AUTOSAR XML (schema 00046)
package /ComponentTypes
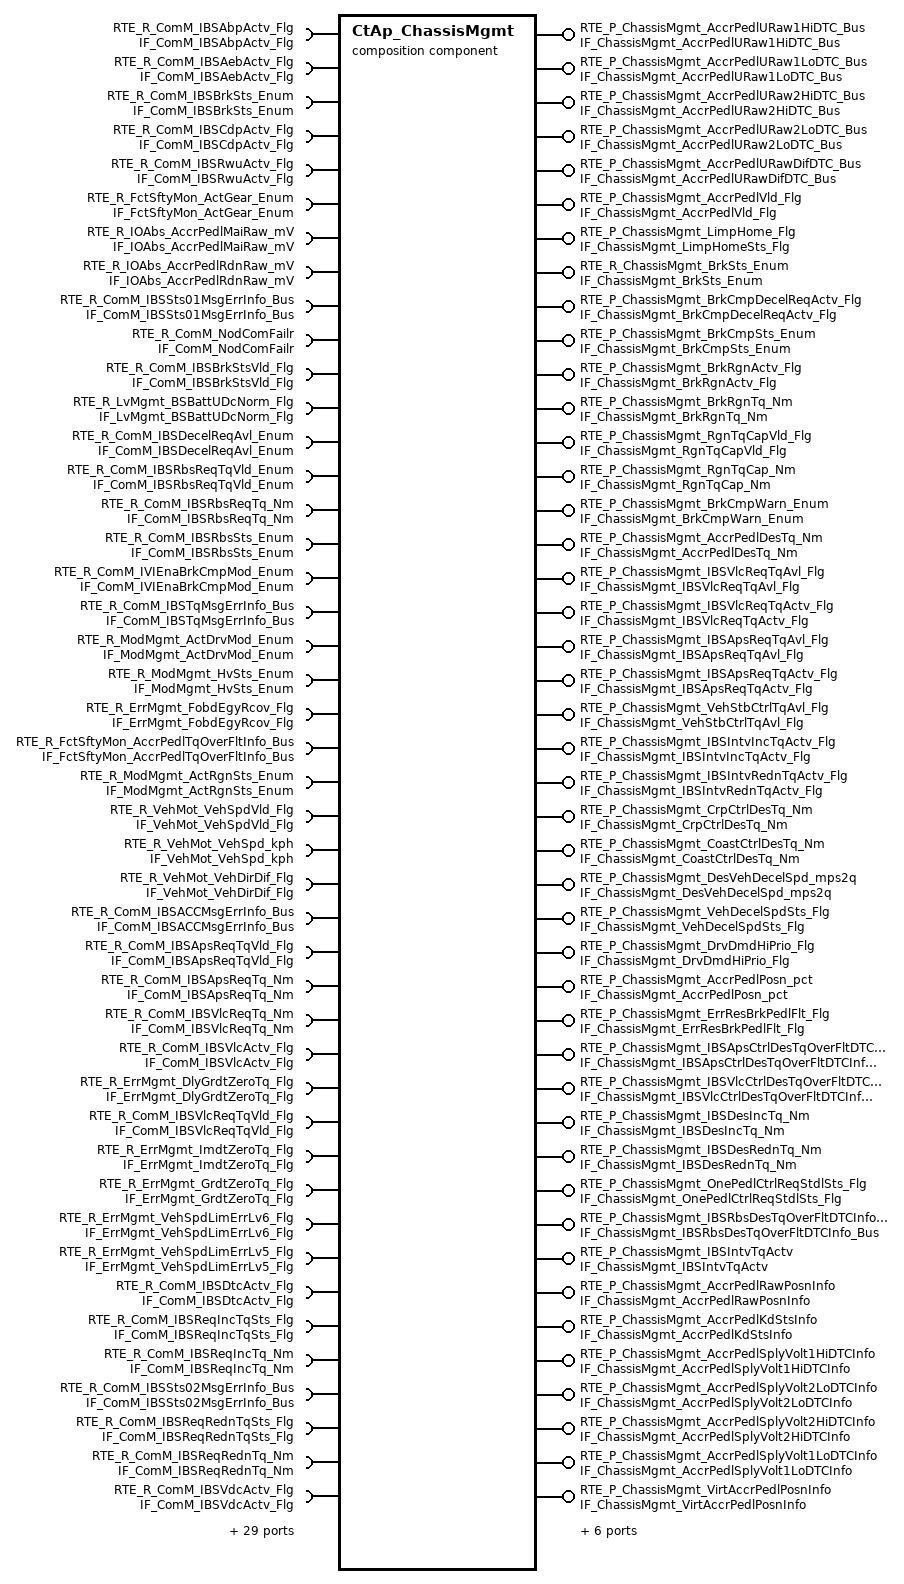
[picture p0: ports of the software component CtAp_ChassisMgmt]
  composition sw component type CtAp_ChassisMgmt
    12 x require port:
      RTE_R_ComM_IBSAbpActv_Flg: nonqueued-receiver-com-spec{data-element=tec_ComM_IBSAbpActv_Flg, filter=data-filter-type=ALWAYS, init-value=0}, required-interface=IF_ComM_IBSAbpActv_Flg
      RTE_R_ComM_IBSAebActv_Flg: nonqueued-receiver-com-spec{data-element=tec_ComM_IBSAebActv_Flg, filter=data-filter-type=ALWAYS, init-value=0}, required-interface=IF_ComM_IBSAebActv_Flg
      RTE_R_ComM_IBSBrkSts_Enum: nonqueued-receiver-com-spec{data-element=tec_ComM_IBSBrkSts_Enum, filter=data-filter-type=ALWAYS, init-value=0}, required-interface=IF_ComM_IBSBrkSts_Enum
      RTE_R_ComM_IBSCdpActv_Flg: nonqueued-receiver-com-spec{data-element=tec_ComM_IBSCdpActv_Flg, filter=data-filter-type=ALWAYS, init-value=0}, required-interface=IF_ComM_IBSCdpActv_Flg
      RTE_R_ComM_IBSRwuActv_Flg: nonqueued-receiver-com-spec{data-element=tec_ComM_IBSRwuActv_Flg, filter=data-filter-type=ALWAYS, init-value=0}, required-interface=IF_ComM_IBSRwuActv_Flg
      RTE_R_FctSftyMon_ActGear_Enum: nonqueued-receiver-com-spec{data-element=tec_FctSftyMon_ActGear_Enum, filter=data-filter-type=ALWAYS, init-value=0}, required-interface=IF_FctSftyMon_ActGear_Enum
      RTE_R_IOAbs_AccrPedlMaiRaw_mV: nonqueued-receiver-com-spec{data-element=tec_IOAbs_AccrPedlMaiRaw_mV, filter=data-filter-type=ALWAYS, init-value=0}, required-interface=IF_IOAbs_AccrPedlMaiRaw_mV
      RTE_R_IOAbs_AccrPedlRdnRaw_mV: nonqueued-receiver-com-spec{data-element=tec_IOAbs_AccrPedlRdnRaw_mV, filter=data-filter-type=ALWAYS, init-value=0}, required-interface=IF_IOAbs_AccrPedlRdnRaw_mV
      RTE_R_ComM_IBSSts01MsgErrInfo_Bus: required-interface=IF_ComM_IBSSts01MsgErrInfo_Bus
        required-com-specs:
          data-element=tec_ComM_IBSSts01CRCDTCInfo_Bus, filter=data-filter-type=ALWAYS, init-value=fields=[ComM_MonStatIBSSts01CRCDTCErrorInfo:0, ComM_MonResIBSSts01CRCDTCErrorInfo:0, ComM_ErrStatIBSSts01CRCDTCErrorInfo:0, ComM_ErrResIBSSts01CRCDTCErrorInfo:0]
          data-element=tec_ComM_IBSSts01TimeoutDTCInfo_Bus, filter=data-filter-type=ALWAYS, init-value=fields=[ComM_MonStatIBSSts01TimeoutDTCErrorInfo:0, ComM_MonResIBSSts01TimeoutDTCErrorInfo:0, ComM_ErrStatIBSSts01TimeoutDTCErrorInfo:0, ComM_ErrResIBSSts01TimeoutDTCErrorInfo:0]
          data-element=tec_ComM_IBSSts01CRCInfo_Bus, filter=data-filter-type=ALWAYS, init-value=fields=[ComM_MonStatIBSSts01CRCErrorInfo:0, ComM_MonResIBSSts01CRCErrorInfo:0, ComM_ErrStatIBSSts01CRCErrorInfo:0, ComM_ErrResIBSSts01CRCErrorInfo:0]
          data-element=tec_ComM_IBSSts01E2ETimeoutInfo_Bus, filter=data-filter-type=ALWAYS, init-value=fields=[ComM_MonStatIBSSts01E2ETimeoutInfo:0, ComM_MonResIBSSts01E2ETimeoutInfo:0, ComM_ErrStatIBSSts01E2ETimeoutInfo:0, ComM_ErrResIBSSts01E2ETimeoutInfo:0]
      RTE_R_ComM_NodComFailr: required-interface=IF_ComM_NodComFailr
        required-com-specs:
          data-element=tec_ComM_SGWNodComFailr_Flg, filter=data-filter-type=ALWAYS, init-value=0
          data-element=tec_ComM_CGWNodComFailr_Flg, filter=data-filter-type=ALWAYS, init-value=0
          data-element=tec_ComM_TCUNodComFailr_Flg, filter=data-filter-type=ALWAYS, init-value=0
          data-element=tec_ComM_BCMNodComFailr_Flg, filter=data-filter-type=ALWAYS, init-value=0
          data-element=tec_ComM_PRNDNodComFailr_Flg, filter=data-filter-type=ALWAYS, init-value=0
          data-element=tec_ComM_IVINodComFailr_Flg, filter=data-filter-type=ALWAYS, init-value=0
          data-element=tec_ComM_DCDCNodComFailr_Flg, filter=data-filter-type=ALWAYS, init-value=0
          data-element=tec_ComM_OBCNodComFailr_Flg, filter=data-filter-type=ALWAYS, init-value=0
          data-element=tec_ComM_CHIBSNodComFailr_Flg, filter=data-filter-type=ALWAYS, init-value=0
          data-element=tec_ComM_MCUNodComFailr_Flg, filter=data-filter-type=ALWAYS, init-value=0
          data-element=tec_ComM_EVCOMNodComFailr_Flg, filter=data-filter-type=ALWAYS, init-value=0
          data-element=tec_ComM_EPTIBSNodComFailr_Flg, filter=data-filter-type=ALWAYS, init-value=0
          data-element=tec_ComM_DCMNodComFailr_Flg, filter=data-filter-type=ALWAYS, init-value=0
          data-element=tec_ComM_BMSNodComFailr_Flg, filter=data-filter-type=ALWAYS, init-value=0
          data-element=tec_ComM_ACUNodComFailr_Flg, filter=data-filter-type=ALWAYS, init-value=0
          data-element=tec_ComM_APTCNodComFailr_Flg, filter=data-filter-type=ALWAYS, init-value=0
          data-element=tec_ComM_ADCUNodComFailr_Flg, filter=data-filter-type=ALWAYS, init-value=0
          data-element=tec_ComM_DCMRRNodComFailr_Flg, filter=data-filter-type=ALWAYS, init-value=0
          data-element=tec_ComM_DCMRLNodComFailr_Flg, filter=data-filter-type=ALWAYS, init-value=0
          data-element=tec_ComM_DCMFRNodComFailr_Flg, filter=data-filter-type=ALWAYS, init-value=0
          data-element=tec_ComM_DCMFLNodComFailr_Flg, filter=data-filter-type=ALWAYS, init-value=0
          data-element=tec_ComM_SGWCHNodComFailr_Flg, filter=data-filter-type=ALWAYS, init-value=0
      RTE_R_ComM_IBSBrkStsVld_Flg: nonqueued-receiver-com-spec{data-element=tec_ComM_IBSBrkStsVld_Flg, filter=data-filter-type=ALWAYS, init-value=0}, required-interface=IF_ComM_IBSBrkStsVld_Flg
      RTE_R_LvMgmt_BSBattUDcNorm_Flg: nonqueued-receiver-com-spec{data-element=tec_LvMgmt_BSBattUDcNorm_Flg, filter=data-filter-type=ALWAYS, init-value=0}, required-interface=IF_LvMgmt_BSBattUDcNorm_Flg
    28 x provide port:
      RTE_P_ChassisMgmt_AccrPedlURaw1HiDTC_Bus: nonqueued-sender-com-spec{data-element=tec_ChassisMgmt_AccrPedlURaw1HiDTC_Bus, init-value=fields=[ChassisMgmt_MonStatAccrPedlURaw1Hi:0, ChassisMgmt_MonResAccrPedlURaw1Hi:0, ChassisMgmt_ErrStatAccrPedlURaw1Hi:0, ChassisMgmt_ErrResAccrPedlURaw1Hi:0]}, provided-interface=IF_ChassisMgmt_AccrPedlURaw1HiDTC_Bus
      RTE_P_ChassisMgmt_AccrPedlURaw1LoDTC_Bus: nonqueued-sender-com-spec{data-element=tec_ChassisMgmt_AccrPedlURaw1LoDTC_Bus, init-value=fields=[ChassisMgmt_MonStatAccrPedlURaw1Lo:0, ChassisMgmt_MonResAccrPedlURaw1Lo:0, ChassisMgmt_ErrStatAccrPedlURaw1Lo:0, ChassisMgmt_ErrResAccrPedlURaw1Lo:0]}, provided-interface=IF_ChassisMgmt_AccrPedlURaw1LoDTC_Bus
      RTE_P_ChassisMgmt_AccrPedlURaw2HiDTC_Bus: nonqueued-sender-com-spec{data-element=tec_ChassisMgmt_AccrPedlURaw2HiDTC_Bus, init-value=fields=[ChassisMgmt_MonStatAccrPedlURaw2Hi:0, ChassisMgmt_MonResAccrPedlURaw2Hi:0, ChassisMgmt_ErrStatAccrPedlURaw2Hi:0, ChassisMgmt_ErrResAccrPedlURaw2Hi:0]}, provided-interface=IF_ChassisMgmt_AccrPedlURaw2HiDTC_Bus
      RTE_P_ChassisMgmt_AccrPedlURaw2LoDTC_Bus: nonqueued-sender-com-spec{data-element=tec_ChassisMgmt_AccrPedlURaw2LoDTC_Bus, init-value=fields=[ChassisMgmt_MonStatAccrPedlURaw2Lo:0, ChassisMgmt_MonResAccrPedlURaw2Lo:0, ChassisMgmt_ErrStatAccrPedlURaw2Lo:0, ChassisMgmt_ErrResAccrPedlURaw2Lo:0]}, provided-interface=IF_ChassisMgmt_AccrPedlURaw2LoDTC_Bus
      RTE_P_ChassisMgmt_AccrPedlURawDifDTC_Bus: nonqueued-sender-com-spec{data-element=tec_ChassisMgmt_AccrPedlURawDifDTC_Bus, init-value=fields=[ChassisMgmt_MonStatAccrPedlURawDif:0, ChassisMgmt_MonResAccrPedlURawDif:0, ChassisMgmt_ErrStatAccrPedlURawDif:0, ChassisMgmt_ErrResAccrPedlURawDif:0]}, provided-interface=IF_ChassisMgmt_AccrPedlURawDifDTC_Bus
      RTE_P_ChassisMgmt_AccrPedlVld_Flg: nonqueued-sender-com-spec{data-element=tec_ChassisMgmt_AccrPedlVld_Flg, init-value=0}, provided-interface=IF_ChassisMgmt_AccrPedlVld_Flg
      RTE_P_ChassisMgmt_LimpHome_Flg: nonqueued-sender-com-spec{data-element=tec_ChassisMgmt_LimpHomeSts_Flg, init-value=0}, provided-interface=IF_ChassisMgmt_LimpHomeSts_Flg
      RTE_R_ChassisMgmt_BrkSts_Enum: nonqueued-sender-com-spec{data-element=tec_ChassisMgmt_BrkSts_Enum, init-value=0}, provided-interface=IF_ChassisMgmt_BrkSts_Enum
      RTE_P_ChassisMgmt_BrkCmpDecelReqActv_Flg: nonqueued-sender-com-spec{data-element=tec_ChassisMgmt_BrkCmpDecelReqActv_Flg, init-value=0}, provided-interface=IF_ChassisMgmt_BrkCmpDecelReqActv_Flg
      RTE_P_ChassisMgmt_BrkCmpSts_Enum: nonqueued-sender-com-spec{data-element=tec_ChassisMgmt_BrkCmpSts_Enum, init-value=0}, provided-interface=IF_ChassisMgmt_BrkCmpSts_Enum
      RTE_P_ChassisMgmt_BrkRgnActv_Flg: nonqueued-sender-com-spec{data-element=tec_ChassisMgmt_BrkRgnActv_Flg, init-value=0}, provided-interface=IF_ChassisMgmt_BrkRgnActv_Flg
      RTE_P_ChassisMgmt_BrkRgnTq_Nm: nonqueued-sender-com-spec{data-element=tec_ChassisMgmt_BrkRgnTq_Nm, init-value=0}, provided-interface=IF_ChassisMgmt_BrkRgnTq_Nm
      RTE_P_ChassisMgmt_RgnTqCapVld_Flg: nonqueued-sender-com-spec{data-element=tec_ChassisMgmt_RgnTqCapVld_Flg, init-value=0}, provided-interface=IF_ChassisMgmt_RgnTqCapVld_Flg
      RTE_P_ChassisMgmt_RgnTqCap_Nm: nonqueued-sender-com-spec{data-element=tec_ChassisMgmt_RgnTqCap_Nm, init-value=0}, provided-interface=IF_ChassisMgmt_RgnTqCap_Nm
      RTE_P_ChassisMgmt_BrkCmpWarn_Enum: nonqueued-sender-com-spec{data-element=tec_ChassisMgmt_BrkCmpWarn_Enum, init-value=0}, provided-interface=IF_ChassisMgmt_BrkCmpWarn_Enum
      RTE_P_ChassisMgmt_AccrPedlDesTq_Nm: nonqueued-sender-com-spec{data-element=tec_ChassisMgmt_AccrPedlDesTq_Nm, init-value=0}, provided-interface=IF_ChassisMgmt_AccrPedlDesTq_Nm
      RTE_P_ChassisMgmt_IBSVlcReqTqAvl_Flg: nonqueued-sender-com-spec{data-element=tec_ChassisMgmt_IBSVlcReqTqAvl_Flg, init-value=0}, provided-interface=IF_ChassisMgmt_IBSVlcReqTqAvl_Flg
      RTE_P_ChassisMgmt_IBSVlcReqTqActv_Flg: nonqueued-sender-com-spec{data-element=tec_ChassisMgmt_IBSVlcReqTqActv_Flg, init-value=0}, provided-interface=IF_ChassisMgmt_IBSVlcReqTqActv_Flg
      RTE_P_ChassisMgmt_IBSApsReqTqAvl_Flg: nonqueued-sender-com-spec{data-element=tec_ChassisMgmt_IBSApsReqTqAvl_Flg, init-value=0}, provided-interface=IF_ChassisMgmt_IBSApsReqTqAvl_Flg
      RTE_P_ChassisMgmt_IBSApsReqTqActv_Flg: nonqueued-sender-com-spec{data-element=tec_ChassisMgmt_IBSApsReqTqActv_Flg, init-value=0}, provided-interface=IF_ChassisMgmt_IBSApsReqTqActv_Flg
      RTE_P_ChassisMgmt_VehStbCtrlTqAvl_Flg: nonqueued-sender-com-spec{data-element=tec_ChassisMgmt_VehStbCtrlTqAvl_Flg, init-value=0}, provided-interface=IF_ChassisMgmt_VehStbCtrlTqAvl_Flg
      RTE_P_ChassisMgmt_IBSIntvIncTqActv_Flg: nonqueued-sender-com-spec{data-element=tec_ChassisMgmt_IBSIntvIncTqActv_Flg, init-value=0}, provided-interface=IF_ChassisMgmt_IBSIntvIncTqActv_Flg
      RTE_P_ChassisMgmt_IBSIntvRednTqActv_Flg: nonqueued-sender-com-spec{data-element=tec_ChassisMgmt_IBSIntvRednTqActv_Flg, init-value=0}, provided-interface=IF_ChassisMgmt_IBSIntvRednTqActv_Flg
      RTE_P_ChassisMgmt_CrpCtrlDesTq_Nm: nonqueued-sender-com-spec{data-element=tec_ChassisMgmt_CrpCtrlDesTq_Nm, init-value=0}, provided-interface=IF_ChassisMgmt_CrpCtrlDesTq_Nm
      RTE_P_ChassisMgmt_CoastCtrlDesTq_Nm: nonqueued-sender-com-spec{data-element=tec_ChassisMgmt_CoastCtrlDesTq_Nm, init-value=0}, provided-interface=IF_ChassisMgmt_CoastCtrlDesTq_Nm
      RTE_P_ChassisMgmt_DesVehDecelSpd_mps2q: nonqueued-sender-com-spec{data-element=tec_ChassisMgmt_DesVehDecelSpd_mps2q, init-value=0}, provided-interface=IF_ChassisMgmt_DesVehDecelSpd_mps2q
      RTE_P_ChassisMgmt_VehDecelSpdSts_Flg: nonqueued-sender-com-spec{data-element=tec_ChassisMgmt_VehDecelSpdSts_Flg, init-value=0}, provided-interface=IF_ChassisMgmt_VehDecelSpdSts_Flg
      RTE_P_ChassisMgmt_DrvDmdHiPrio_Flg: nonqueued-sender-com-spec{data-element=tec_ChassisMgmt_DrvDmdHiPrio_Flg, init-value=0}, provided-interface=IF_ChassisMgmt_DrvDmdHiPrio_Flg
    43 x require port:
      RTE_R_ComM_IBSDecelReqAvl_Enum: nonqueued-receiver-com-spec{data-element=tec_ComM_IBSDecelReqAvl_Enum, filter=data-filter-type=ALWAYS, init-value=0}, required-interface=IF_ComM_IBSDecelReqAvl_Enum
      RTE_R_ComM_IBSRbsReqTqVld_Enum: nonqueued-receiver-com-spec{data-element=tec_ComM_IBSRbsReqTqVld_Enum, filter=data-filter-type=ALWAYS, init-value=0}, required-interface=IF_ComM_IBSRbsReqTqVld_Enum
      RTE_R_ComM_IBSRbsReqTq_Nm: nonqueued-receiver-com-spec{data-element=tec_ComM_IBSRbsReqTq_Nm, filter=data-filter-type=ALWAYS, init-value=0}, required-interface=IF_ComM_IBSRbsReqTq_Nm
      RTE_R_ComM_IBSRbsSts_Enum: nonqueued-receiver-com-spec{data-element=tec_ComM_IBSRbsSts_Enum, filter=data-filter-type=ALWAYS, init-value=0}, required-interface=IF_ComM_IBSRbsSts_Enum
      RTE_R_ComM_IVIEnaBrkCmpMod_Enum: nonqueued-receiver-com-spec{data-element=tec_ComM_IVIEnaBrkCmpMod_Enum, filter=data-filter-type=ALWAYS, init-value=0}, required-interface=IF_ComM_IVIEnaBrkCmpMod_Enum
      RTE_R_ComM_IBSTqMsgErrInfo_Bus: required-interface=IF_ComM_IBSTqMsgErrInfo_Bus
        required-com-specs:
          data-element=tec_ComM_IBSTqCRCDTCInfo_Bus, filter=data-filter-type=ALWAYS, init-value=fields=[ComM_MonStatIBSTqCRCDTCErrorInfo:0, ComM_MonResIBSTqCRCDTCErrorInfo:0, ComM_ErrStatIBSTqCRCDTCErrorInfo:0, ComM_ErrResIBSTqCRCDTCErrorInfo:0]
          data-element=tec_ComM_IBSTqTimeoutDTCInfo_Bus, filter=data-filter-type=ALWAYS, init-value=fields=[ComM_MonStatIBSTqTimeoutDTCErrorInfo:0, ComM_MonResIBSTqTimeoutDTCErrorInfo:0, ComM_ErrStatIBSTqTimeoutDTCErrorInfo:0, ComM_ErrResIBSTqTimeoutDTCErrorInfo:0]
          data-element=tec_ComM_IBSTqCRCInfo_Bus, filter=data-filter-type=ALWAYS, init-value=fields=[ComM_MonStatIBSTqCRCErrorInfo:0, ComM_MonResIBSTqCRCErrorInfo:0, ComM_ErrStatIBSTqCRCErrorInfo:0, ComM_ErrResIBSTqCRCErrorInfo:0]
          data-element=tec_ComM_IBSTqE2ETimeoutInfo_Bus, filter=data-filter-type=ALWAYS, init-value=fields=[ComM_MonStatIBSTqE2ETimeoutInfo:0, ComM_MonResIBSTqE2ETimeoutInfo:0, ComM_ErrStatIBSTqE2ETimeoutInfo:0, ComM_ErrResIBSTqE2ETimeoutInfo:0]
      RTE_R_ModMgmt_ActDrvMod_Enum: nonqueued-receiver-com-spec{data-element=tec_ModMgmt_ActDrvMod_Enum, filter=data-filter-type=ALWAYS, init-value=0}, required-interface=IF_ModMgmt_ActDrvMod_Enum
      RTE_R_ModMgmt_HvSts_Enum: nonqueued-receiver-com-spec{data-element=tec_ModMgmt_HvSts_Enum, filter=data-filter-type=ALWAYS, init-value=0}, required-interface=IF_ModMgmt_HvSts_Enum
      RTE_R_ErrMgmt_FobdEgyRcov_Flg: nonqueued-receiver-com-spec{data-element=tec_ErrMgmt_FobdEgyRcov_Flg, filter=data-filter-type=ALWAYS, init-value=0}, required-interface=IF_ErrMgmt_FobdEgyRcov_Flg
      RTE_R_FctSftyMon_AccrPedlTqOverFltInfo_Bus: nonqueued-receiver-com-spec{data-element=tec_FctSftyMon_AccrPedlTqOverFltInfo_Bus, filter=data-filter-type=ALWAYS, init-value=fields=[FctSftyMon_MonStatAccrPedlTqOverFltInfo:0, FctSftyMon_MonResAccrPedlTqOverFltInfo:0, FctSftyMon_ErrStatAccrPedlTqOverFltInfo:0, FctSftyMon_ErrResAccrPedlTqOverFltInfo:0]}, required-interface=IF_FctSftyMon_AccrPedlTqOverFltInfo_Bus
      RTE_R_ModMgmt_ActRgnSts_Enum: nonqueued-receiver-com-spec{data-element=tec_ModMgmt_ActRgnSts_Enum, filter=data-filter-type=ALWAYS, init-value=0}, required-interface=IF_ModMgmt_ActRgnSts_Enum
      RTE_R_VehMot_VehSpdVld_Flg: nonqueued-receiver-com-spec{data-element=tec_VehMot_VehSpdVld_Flg, filter=data-filter-type=ALWAYS, init-value=0}, required-interface=IF_VehMot_VehSpdVld_Flg
      RTE_R_VehMot_VehSpd_kph: nonqueued-receiver-com-spec{data-element=tec_VehMot_VehSpd_kph, filter=data-filter-type=ALWAYS, init-value=0}, required-interface=IF_VehMot_VehSpd_kph
      RTE_R_VehMot_VehDirDif_Flg: nonqueued-receiver-com-spec{data-element=tec_VehMot_VehDirDif_Flg, filter=data-filter-type=ALWAYS, init-value=0}, required-interface=IF_VehMot_VehDirDif_Flg
      RTE_R_ComM_IBSACCMsgErrInfo_Bus: required-interface=IF_ComM_IBSACCMsgErrInfo_Bus
        required-com-specs:
          data-element=tec_ComM_IBSACCCRCDTCInfo_Bus, filter=data-filter-type=ALWAYS, init-value=fields=[ComM_MonStatIBSACCCRCDTCErrorInfo:0, ComM_MonResIBSACCCRCDTCErrorInfo:0, ComM_ErrStatIBSACCCRCDTCErrorInfo:0, ComM_ErrResIBSACCCRCDTCErrorInfo:0]
          data-element=tec_ComM_IBSACCCRCInfo_Bus, filter=data-filter-type=ALWAYS, init-value=fields=[ComM_MonStatIBSACCCRCErrorInfo:0, ComM_MonResIBSACCCRCErrorInfo:0, ComM_ErrStatIBSACCCRCErrorInfo:0, ComM_ErrResIBSACCCRCErrorInfo:0]
          data-element=tec_ComM_IBSACCTimeoutDTCInfo_Bus, filter=data-filter-type=ALWAYS, init-value=fields=[ComM_MonStatIBSACCTimeoutDTCErrorInfo:0, ComM_MonResIBSACCTimeoutDTCErrorInfo:0, ComM_ErrStatIBSACCTimeoutDTCErrorInfo:0, ComM_ErrResIBSACCTimeoutDTCErrorInfo:0]
          data-element=tec_ComM_IBSACCE2ETimeoutInfo_Bus, filter=data-filter-type=ALWAYS, init-value=fields=[ComM_MonStatIBSACCE2ETimeoutInfo:0, ComM_MonResIBSACCE2ETimeoutInfo:0, ComM_ErrStatIBSACCE2ETimeoutInfo:0, ComM_ErrResIBSACCE2ETimeoutInfo:0]
      RTE_R_ComM_IBSApsReqTqVld_Flg: nonqueued-receiver-com-spec{data-element=tec_ComM_IBSApsReqTqVld_Flg, filter=data-filter-type=ALWAYS, init-value=0}, required-interface=IF_ComM_IBSApsReqTqVld_Flg
      RTE_R_ComM_IBSApsReqTq_Nm: nonqueued-receiver-com-spec{data-element=tec_ComM_IBSApsReqTq_Nm, filter=data-filter-type=ALWAYS, init-value=0}, required-interface=IF_ComM_IBSApsReqTq_Nm
      RTE_R_ComM_IBSVlcReqTq_Nm: nonqueued-receiver-com-spec{data-element=tec_ComM_IBSVlcReqTq_Nm, filter=data-filter-type=ALWAYS, init-value=0}, required-interface=IF_ComM_IBSVlcReqTq_Nm
      RTE_R_ComM_IBSVlcActv_Flg: nonqueued-receiver-com-spec{data-element=tec_ComM_IBSVlcActv_Flg, filter=data-filter-type=ALWAYS, init-value=0}, required-interface=IF_ComM_IBSVlcActv_Flg
      RTE_R_ErrMgmt_DlyGrdtZeroTq_Flg: nonqueued-receiver-com-spec{data-element=tec_ErrMgmt_DlyGrdtZeroTq_Flg, filter=data-filter-type=ALWAYS, init-value=0}, required-interface=IF_ErrMgmt_DlyGrdtZeroTq_Flg
      RTE_R_ComM_IBSVlcReqTqVld_Flg: nonqueued-receiver-com-spec{data-element=tec_ComM_IBSVlcReqTqVld_Flg, filter=data-filter-type=ALWAYS, init-value=0}, required-interface=IF_ComM_IBSVlcReqTqVld_Flg
      RTE_R_ErrMgmt_ImdtZeroTq_Flg: nonqueued-receiver-com-spec{data-element=tec_ErrMgmt_ImdtZeroTq_Flg, filter=data-filter-type=ALWAYS, init-value=0}, required-interface=IF_ErrMgmt_ImdtZeroTq_Flg
      RTE_R_ErrMgmt_GrdtZeroTq_Flg: nonqueued-receiver-com-spec{data-element=tec_ErrMgmt_GrdtZeroTq_Flg, filter=data-filter-type=ALWAYS, init-value=0}, required-interface=IF_ErrMgmt_GrdtZeroTq_Flg
      RTE_R_ErrMgmt_VehSpdLimErrLv6_Flg: nonqueued-receiver-com-spec{data-element=tec_ErrMgmt_VehSpdLimErrLv6_Flg, filter=data-filter-type=ALWAYS, init-value=0}, required-interface=IF_ErrMgmt_VehSpdLimErrLv6_Flg
      RTE_R_ErrMgmt_VehSpdLimErrLv5_Flg: nonqueued-receiver-com-spec{data-element=tec_ErrMgmt_VehSpdLimErrLv5_Flg, filter=data-filter-type=ALWAYS, init-value=0}, required-interface=IF_ErrMgmt_VehSpdLimErrLv5_Flg
      RTE_R_ComM_IBSDtcActv_Flg: nonqueued-receiver-com-spec{data-element=tec_ComM_IBSDtcActv_Flg, filter=data-filter-type=ALWAYS, init-value=0}, required-interface=IF_ComM_IBSDtcActv_Flg
      RTE_R_ComM_IBSReqIncTqSts_Flg: nonqueued-receiver-com-spec{data-element=tec_ComM_IBSReqIncTqSts_Flg, filter=data-filter-type=ALWAYS, init-value=0}, required-interface=IF_ComM_IBSReqIncTqSts_Flg
      RTE_R_ComM_IBSReqIncTq_Nm: nonqueued-receiver-com-spec{data-element=tec_ComM_IBSReqIncTq_Nm, filter=data-filter-type=ALWAYS, init-value=0}, required-interface=IF_ComM_IBSReqIncTq_Nm
      RTE_R_ComM_IBSSts02MsgErrInfo_Bus: required-interface=IF_ComM_IBSSts02MsgErrInfo_Bus
        required-com-specs:
          data-element=tec_ComM_IBSSts02CRCInfo_Bus, filter=data-filter-type=ALWAYS, init-value=fields=[ComM_MonStatIBSSts02CRCErrorInfo:0, ComM_MonResIBSSts02CRCErrorInfo:0, ComM_ErrStatIBSSts02CRCErrorInfo:0, ComM_ErrResIBSSts02CRCErrorInfo:0]
          data-element=tec_ComM_IBSSts02CRCDTCInfo_Bus, filter=data-filter-type=ALWAYS, init-value=fields=[ComM_MonStatIBSSts02CRCDTCErrorInfo:0, ComM_MonResIBSSts02CRCDTCErrorInfo:0, ComM_ErrStatIBSSts02CRCDTCErrorInfo:0, ComM_ErrResIBSSts02CRCDTCErrorInfo:0]
          data-element=tec_ComM_IBSSts02TimeoutDTCInfo_Bus, filter=data-filter-type=ALWAYS, init-value=fields=[ComM_MonStatIBSSts02TimeoutDTCErrorInfo:0, ComM_MonResIBSSts02TimeoutDTCErrorInfo:0, ComM_ErrStatIBSSts02TimeoutDTCErrorInfo:0, ComM_ErrResIBSSts02TimeoutDTCErrorInfo:0]
          data-element=tec_ComM_IBSSts02E2ETimeoutInfo_Bus, filter=data-filter-type=ALWAYS, init-value=fields=[ComM_MonStatIBSSts02E2ETimeoutInfo:0, ComM_MonResIBSSts02E2ETimeoutInfo:0, ComM_ErrStatIBSSts02E2ETimeoutInfo:0, ComM_ErrResIBSSts02E2ETimeoutInfo:0]
      RTE_R_ComM_IBSReqRednTqSts_Flg: nonqueued-receiver-com-spec{data-element=tec_ComM_IBSReqRednTqSts_Flg, filter=data-filter-type=ALWAYS, init-value=0}, required-interface=IF_ComM_IBSReqRednTqSts_Flg
      RTE_R_ComM_IBSReqRednTq_Nm: nonqueued-receiver-com-spec{data-element=tec_ComM_IBSReqRednTq_Nm, filter=data-filter-type=ALWAYS, init-value=0}, required-interface=IF_ComM_IBSReqRednTq_Nm
      RTE_R_ComM_IBSVdcActv_Flg: nonqueued-receiver-com-spec{data-element=tec_ComM_IBSVdcActv_Flg, filter=data-filter-type=ALWAYS, init-value=0}, required-interface=IF_ComM_IBSVdcActv_Flg
      RTE_R_ComM_IBSVCUMotCtrlMsgErrInfo_Bus: required-interface=IF_ComM_IBSVCUMotCtrlMsgErrInfo_Bus
        required-com-specs:
          data-element=tec_ComM_IBSVCUMotCtrlCRCDTCInfo_Bus, filter=data-filter-type=ALWAYS, init-value=fields=[ComM_MonStatIBSVCUMotCtrlCRCDTCErrorInfo:0, ComM_MonResIBSVCUMotCtrlCRCDTCErrorInfo:0, ComM_ErrStatIBSVCUMotCtrlCRCDTCErrorInfo:0, ComM_ErrResIBSVCUMotCtrlCRCDTCErrorInfo:0]
          data-element=tec_ComM_IBSVCUMotCtrlTimeoutInfo_Bus, filter=data-filter-type=ALWAYS, init-value=fields=[ComM_MonStatIBSVCUMotCtrlTimeoutInfo:0, ComM_MonResIBSVCUMotCtrlTimeoutInfo:0, ComM_ErrStatIBSVCUMotCtrlTimeoutInfo:0, ComM_ErrResIBSVCUMotCtrlTimeoutInfo:0]
          data-element=tec_ComM_IBSVCUMotCtrlCRCInfo_Bus, filter=data-filter-type=ALWAYS, init-value=fields=[ComM_MonStatIBSVCUMotCtrlCRCErrorInfo:0, ComM_MonResIBSVCUMotCtrlCRCErrorInfo:0, ComM_ErrStatIBSVCUMotCtrlCRCErrorInfo:0, ComM_ErrResIBSVCUMotCtrlCRCErrorInfo:0]
          data-element=tec_ComM_IBSVCUMotCtrlTimeoutDTCInfo_Bus, filter=data-filter-type=ALWAYS, init-value=fields=[ComM_MonStatIBSVCUMotCtrlTimeoutDTCErrorInfo:0, ComM_MonResIBSVCUMotCtrlTimeoutDTCErrorInfo:0, ComM_ErrStatIBSVCUMotCtrlTimeoutDTCErrorInfo:0, ComM_ErrResIBSVCUMotCtrlTimeoutDTCErrorInfo:0]
          data-element=tec_ComM_IBSVCUMotCtrlE2ETimeoutInfo_Bus, filter=data-filter-type=ALWAYS, init-value=fields=[ComM_MonStatIBSVCUMotCtrlE2ETimeoutInfo:0, ComM_MonResIBSVCUMotCtrlE2ETimeoutInfo:0, ComM_ErrStatIBSVCUMotCtrlE2ETimeoutInfo:0, ComM_ErrResIBSVCUMotCtrlE2ETimeoutInfo:0]
      RTE_R_ComM_IBSTcsActv_Flg: nonqueued-receiver-com-spec{data-element=tec_ComM_IBSTcsActv_Flg, filter=data-filter-type=ALWAYS, init-value=0}, required-interface=IF_ComM_IBSTcsActv_Flg
      RTE_R_ComM_IBSAvhSts_Enum: nonqueued-receiver-com-spec{data-element=tec_ComM_IBSAvhSts_Enum, filter=data-filter-type=ALWAYS, init-value=0}, required-interface=IF_ComM_IBSAvhSts_Enum
      RTE_R_ComM_IBSHdcSts_Enum: nonqueued-receiver-com-spec{data-element=tec_ComM_IBSHdcSts_Enum, filter=data-filter-type=ALWAYS, init-value=0}, required-interface=IF_ComM_IBSHdcSts_Enum
      RTE_R_ComM_IBSPlgrPrs_Bar: nonqueued-receiver-com-spec{data-element=tec_ComM_IBSPlgrPrs_Bar, filter=data-filter-type=ALWAYS, init-value=0}, required-interface=IF_ComM_IBSPlgrPrs_Bar
      RTE_R_VehMot_SlopGrd_pct: nonqueued-receiver-com-spec{data-element=tec_VehMot_SlopGrd_pct, filter=data-filter-type=ALWAYS, init-value=0}, required-interface=IF_VehMot_SlopGrd_pct
      RTE_R_ComM_IBSApsTqActv_Flg: nonqueued-receiver-com-spec{data-element=tec_ComM_IBSApsTqActv_Flg, filter=data-filter-type=ALWAYS, init-value=0}, required-interface=IF_ComM_IBSApsTqActv_Flg
      RTE_R_FctSftyMon_CrpCtrlTqOverFltInfo_Bus: nonqueued-receiver-com-spec{data-element=tec_FctSftyMon_CrpCtrlTqOverFltInfo_Bus, filter=data-filter-type=ALWAYS, init-value=fields=[FctSftyMon_MonStatCrpCtrlTqOverFltInfo:0, FctSftyMon_MonResCrpCtrlTqOverFltInfo:0, FctSftyMon_ErrStatCrpCtrlTqOverFltInfo:0, FctSftyMon_ErrResCrpCtrlTqOverFltInfo:0]}, required-interface=IF_FctSftyMon_CrpCtrlTqOverFltInfo_Bus
      RTE_R_VehMot_VehStdl_Flg: nonqueued-receiver-com-spec{data-element=tec_VehMot_VehStdl_Flg, filter=data-filter-type=ALWAYS, init-value=0}, required-interface=IF_VehMot_VehStdl_Flg
      RTE_R_FctSftyMon_DesVehDecelSpdOverFltInfo_Bus: nonqueued-receiver-com-spec{data-element=tec_FctSftyMon_DesVehDecelSpdOverFltInfo_Bus, filter=data-filter-type=ALWAYS, init-value=fields=[FctSftyMon_MonStatDesVehDecelSpdOverFltInfo:0, FctSftyMon_MonResDesVehDecelSpdOverFltInfo:0, FctSftyMon_ErrStatDesVehDecelSpdOverFltInfo:0, FctSftyMon_ErrResDesVehDecelSpdOverFltInfo:0]}, required-interface=IF_FctSftyMon_DesVehDecelSpdOverFltInfo_Bus
      RTE_R_TorqPahMgmt_MaxVehSpdLmtTq_Nm: nonqueued-receiver-com-spec{data-element=tec_TorqPahMgmt_MaxVehSpdLmtTq_Nm, filter=data-filter-type=ALWAYS, init-value=0}, required-interface=IF_TorqPahMgmt_MaxVehSpdLmtTq_Nm
    provide port RTE_P_ChassisMgmt_AccrPedlPosn_pct: nonqueued-sender-com-spec{data-element=tec_ChassisMgmt_AccrPedlPosn_pct, init-value=0}, provided-interface=IF_ChassisMgmt_AccrPedlPosn_pct
    provide port RTE_P_ChassisMgmt_ErrResBrkPedlFlt_Flg: nonqueued-sender-com-spec{data-element=tec_ChassisMgmt_ErrResBrkPedlFlt_Flg, init-value=0}, provided-interface=IF_ChassisMgmt_ErrResBrkPedlFlt_Flg
    require port RTE_R_TorqPahMgmt_EmacQstyMaxTq_Nm: nonqueued-receiver-com-spec{data-element=tec_TorqPahMgmt_EmacQstyMaxTq_Nm, filter=data-filter-type=ALWAYS, init-value=0}, required-interface=IF_TorqPahMgmt_EmacQstyMaxTq_Nm
    require port RTE_R_TorqPahMgmt_EmacQstyMinTq_Nm: nonqueued-receiver-com-spec{data-element=tec_TorqPahMgmt_EmacQstyMinTq_Nm, filter=data-filter-type=ALWAYS, init-value=0}, required-interface=IF_TorqPahMgmt_EmacQstyMinTq_Nm
    5 x provide port:
      RTE_P_ChassisMgmt_IBSApsCtrlDesTqOverFltDTCInfo_Bus: nonqueued-sender-com-spec{data-element=tec_ChassisMgmt_IBSApsCtrlDesTqOverFltDTCInfo_Bus, init-value=fields=[ChassisMgmt_MonStatIBSApsCtrlDesTqOverFltDTCInfo:0, ChassisMgmt_MonResIBSApsCtrlDesTqOverFltDTCInfo:0, ChassisMgmt_ErrStatIBSApsCtrlDesTqOverFltDTCInfo:0, ChassisMgmt_ErrResIBSApsCtrlDesTqOverFltDTCInfo:0]}, provided-interface=IF_ChassisMgmt_IBSApsCtrlDesTqOverFltDTCInfo_Bus
      RTE_P_ChassisMgmt_IBSVlcCtrlDesTqOverFltDTCInfo_Bus: nonqueued-sender-com-spec{data-element=tec_ChassisMgmt_IBSVlcCtrlDesTqOverFltDTCInfo_Bus, init-value=fields=[ChassisMgmt_MonStatIBSVlcCtrlDesTqOverFltDTCInfo:0, ChassisMgmt_MonResIBSVlcCtrlDesTqOverFltDTCInfo:0, ChassisMgmt_ErrStatIBSVlcCtrlDesTqOverFltDTCInfo:0, ChassisMgmt_ErrResIBSVlcCtrlDesTqOverFltDTCInfo:0]}, provided-interface=IF_ChassisMgmt_IBSVlcCtrlDesTqOverFltDTCInfo_Bus
      RTE_P_ChassisMgmt_IBSDesIncTq_Nm: nonqueued-sender-com-spec{data-element=tec_ChassisMgmt_IBSDesIncTq_Nm, init-value=0}, provided-interface=IF_ChassisMgmt_IBSDesIncTq_Nm
      RTE_P_ChassisMgmt_IBSDesRednTq_Nm: nonqueued-sender-com-spec{data-element=tec_ChassisMgmt_IBSDesRednTq_Nm, init-value=0}, provided-interface=IF_ChassisMgmt_IBSDesRednTq_Nm
      RTE_P_ChassisMgmt_OnePedlCtrlReqStdlSts_Flg: nonqueued-sender-com-spec{data-element=tec_ChassisMgmt_OnePedlCtrlReqStdlSts_Flg, init-value=0}, provided-interface=IF_ChassisMgmt_OnePedlCtrlReqStdlSts_Flg
    require port RTE_R_VehMot_Acclr2Tq_Nm: nonqueued-receiver-com-spec{data-element=tec_VehMot_Acclr2Tq_Nm, filter=data-filter-type=ALWAYS, init-value=0}, required-interface=IF_VehMot_Acclr2Tq_Nm
    provide port RTE_P_ChassisMgmt_IBSRbsDesTqOverFltDTCInfo_Bus: nonqueued-sender-com-spec{data-element=tec_ChassisMgmt_IBSRbsDesTqOverFltDTCInfo_Bus, init-value=fields=[ChassisMgmt_MonStatIBSRbsDesTqOverFltDTCInfo:0, ChassisMgmt_MonResIBSRbsDesTqOverFltDTCInfo:0, ChassisMgmt_ErrStatIBSRbsDesTqOverFltDTCInfo:0, ChassisMgmt_ErrResIBSRbsDesTqOverFltDTCInfo:0]}, provided-interface=IF_ChassisMgmt_IBSRbsDesTqOverFltDTCInfo_Bus
    require port RTE_R_ComM_IBSSts04MsgErrInfo_Bus: required-interface=IF_ComM_IBSSts04MsgErrInfo_Bus
      required-com-specs:
        data-element=tec_ComM_IBSSts04CRCDTCInfo_Bus, filter=data-filter-type=ALWAYS, init-value=fields=[ComM_MonStatIBSSts04CRCDTCErrorInfo:0, ComM_MonResIBSSts04CRCDTCErrorInfo:0, ComM_ErrStatIBSSts04CRCDTCErrorInfo:0, ComM_ErrResIBSSts04CRCDTCErrorInfo:0]
        data-element=tec_ComM_IBSSts04CRCInfo_Bus, filter=data-filter-type=ALWAYS, init-value=fields=[ComM_MonStatIBSSts04CRCErrorInfo:0, ComM_MonResIBSSts04CRCErrorInfo:0, ComM_ErrStatIBSSts04CRCErrorInfo:0, ComM_ErrResIBSSts04CRCErrorInfo:0]
        data-element=tec_ComM_IBSSts04TimeoutDTCInfo_Bus, filter=data-filter-type=ALWAYS, init-value=fields=[ComM_MonStatIBSSts04TimeoutDTCErrorInfo:0, ComM_MonResIBSSts04TimeoutDTCErrorInfo:0, ComM_ErrStatIBSSts04TimeoutDTCErrorInfo:0, ComM_ErrResIBSSts04TimeoutDTCErrorInfo:0]
        data-element=tec_ComM_IBSSts04E2ETimeoutInfo_Bus, filter=data-filter-type=ALWAYS, init-value=fields=[ComM_MonStatIBSSts04E2ETimeoutInfo:0, ComM_MonResIBSSts04E2ETimeoutInfo:0, ComM_ErrStatIBSSts04E2ETimeoutInfo:0, ComM_ErrResIBSSts04E2ETimeoutInfo:0]
    provide port RTE_P_ChassisMgmt_IBSIntvTqActv: nonqueued-sender-com-spec{data-element=tec_ChassisMgmt_IBSIntvTqActv, init-value=0}, provided-interface=IF_ChassisMgmt_IBSIntvTqActv
    require port RTE_R_IOAbs_AccrPedl1SplyVoltInfo: nonqueued-receiver-com-spec{data-element=tec_IOAbs_AccrPedl1SplyVoltInfo, filter=data-filter-type=ALWAYS, init-value=0}, required-interface=IF_IOAbs_AccrPedl1SplyVoltInfo
    require port RTE_R_IOAbs_AccrPedl2SplyVoltInfo: nonqueued-receiver-com-spec{data-element=tec_IOAbs_AccrPedl2SplyVoltInfo, filter=data-filter-type=ALWAYS, init-value=0}, required-interface=IF_IOAbs_AccrPedl2SplyVoltInfo
    require port RTE_R_DiagApp_DisableDCMReqInfo: nonqueued-receiver-com-spec{data-element=tec_DiagApp_DisableDCMReqInfo, filter=data-filter-type=ALWAYS, init-value=0}, required-interface=IF_DiagApp_DisableDCMReqInfo
    6 x provide port:
      RTE_P_ChassisMgmt_AccrPedlRawPosnInfo: nonqueued-sender-com-spec{data-element=tec_ChassisMgmt_AccrPedlRawPosnInfo, init-value=0}, provided-interface=IF_ChassisMgmt_AccrPedlRawPosnInfo
      RTE_P_ChassisMgmt_AccrPedlKdStsInfo: nonqueued-sender-com-spec{data-element=tec_ChassisMgmt_AccrPedlKdStsInfo, init-value=0}, provided-interface=IF_ChassisMgmt_AccrPedlKdStsInfo
      RTE_P_ChassisMgmt_AccrPedlSplyVolt1HiDTCInfo: nonqueued-sender-com-spec{data-element=tec_ChassisMgmt_AccrPedlSplyVolt1HiDTCInfo, init-value=fields=[ChassisMgmt_MonStatAccrPedlSplyVolt1HiInfo:0, ChassisMgmt_MonResAccrPedlSplyVolt1HiInfo:0, ChassisMgmt_ErrStatAccrPedlSplyVolt1HiInfo:0, ChassisMgmt_ErrResAccrPedlSplyVolt1HiInfo:0]}, provided-interface=IF_ChassisMgmt_AccrPedlSplyVolt1HiDTCInfo
      RTE_P_ChassisMgmt_AccrPedlSplyVolt2LoDTCInfo: nonqueued-sender-com-spec{data-element=tec_ChassisMgmt_AccrPedlSplyVolt2LoDTCInfo, init-value=fields=[ChassisMgmt_MonStatAccrPedlSplyVolt2LoInfo:0, ChassisMgmt_MonResAccrPedlSplyVolt2LoInfo:0, ChassisMgmt_ErrStatAccrPedlSplyVolt2LoInfo:0, ChassisMgmt_ErrResAccrPedlSplyVolt2LoInfo:0]}, provided-interface=IF_ChassisMgmt_AccrPedlSplyVolt2LoDTCInfo
      RTE_P_ChassisMgmt_AccrPedlSplyVolt2HiDTCInfo: nonqueued-sender-com-spec{data-element=tec_ChassisMgmt_AccrPedlSplyVolt2HiDTCInfo, init-value=fields=[ChassisMgmt_MonStatAccrPedlSplyVolt2HiInfo:0, ChassisMgmt_MonResAccrPedlSplyVolt2HiInfo:0, ChassisMgmt_ErrStatAccrPedlSplyVolt2HiInfo:0, ChassisMgmt_ErrResAccrPedlSplyVolt2HiInfo:0]}, provided-interface=IF_ChassisMgmt_AccrPedlSplyVolt2HiDTCInfo
      RTE_P_ChassisMgmt_AccrPedlSplyVolt1LoDTCInfo: nonqueued-sender-com-spec{data-element=tec_ChassisMgmt_AccrPedlSplyVolt1LoDTCInfo, init-value=fields=[ChassisMgmt_MonStatAccrPedlSplyVolt1LoInfo:0, ChassisMgmt_MonResAccrPedlSplyVolt1LoInfo:0, ChassisMgmt_ErrStatAccrPedlSplyVolt1LoInfo:0, ChassisMgmt_ErrResAccrPedlSplyVolt1LoInfo:0]}, provided-interface=IF_ChassisMgmt_AccrPedlSplyVolt1LoDTCInfo
    require port RTE_R_ComM_IBSCddActvInfo: nonqueued-receiver-com-spec{data-element=tec_ComM_IBSCddActvInfo, filter=data-filter-type=ALWAYS, init-value=0}, required-interface=IF_ComM_IBSCddActvInfo
    5 x provide port:
      RTE_P_ChassisMgmt_VirtAccrPedlPosnInfo: nonqueued-sender-com-spec{data-element=tec_ChassisMgmt_VirtAccrPedlPosnInfo, init-value=0}, provided-interface=IF_ChassisMgmt_VirtAccrPedlPosnInfo
      RTE_P_ChassisMgmt_VirtAccrPedlVldInfo: nonqueued-sender-com-spec{data-element=tec_ChassisMgmt_VirtAccrPedlVldInfo, init-value=0}, provided-interface=IF_ChassisMgmt_VirtAccrPedlVldInfo
      RTE_P_ChassisMgmt_DrvAsscCtrlOvrdSts_Flg_1: nonqueued-sender-com-spec{data-element=tec_ChassisMgmt_DrvAsscCtrlOvrdSts_Flg, init-value=0}, provided-interface=IF_ChassisMgmt_DrvAsscCtrlOvrdSts_Flg
      RTE_P_ChassisMgmt_IBSVlcDesTq_Nm: nonqueued-sender-com-spec{data-element=tec_ChassisMgmt_IBSVlcDesTq_Nm, init-value=0}, provided-interface=IF_ChassisMgmt_IBSVlcDesTq_Nm
      RTE_P_ChassisMgmt_IBSApsDesTq_Nm: nonqueued-sender-com-spec=tec_ChassisMgmt_IBSApsDesTq_Nm, provided-interface=IF_ChassisMgmt_IBSApsDesTq_Nm
    require port RTE_R_ComM_MotActTq_Nm: nonqueued-receiver-com-spec{data-element=tec_ComM_MotActTq_Nm, filter=data-filter-type=ALWAYS, init-value=0}, required-interface=IF_ComM_MotActTq_Nm
    require port RTE_R_VehMot_VehDragTq_Nm: nonqueued-receiver-com-spec{data-element=tec_VehMot_VehDragTq_Nm, filter=data-filter-type=ALWAYS, init-value=0}, required-interface=IF_VehMot_VehDragTq_Nm
    provide port RTE_P_ChassisMgmt_DrvCoorrDesTq_Nm: nonqueued-sender-com-spec{data-element=tec_ChassisMgmt_DrvCoorrDesTq_Nm, init-value=0}, provided-interface=IF_ChassisMgmt_DrvCoorrDesTq_Nm
    provide/require port RTE_RP_ChassisMgmtInfo:
      nv-provide-com-spec{ram-block-init-value=fields=[ChassisMgmt_BrkCmpStsInfo:2, ChassisMgmt_FillAdressInfo:0], rom-block-init-value=fields=[ChassisMgmt_BrkCmpStsInfo:2, ChassisMgmt_FillAdressInfo:0], variable=tec_ChassisMgmtInfo}
      nv-require-com-spec{init-value=fields=[ChassisMgmt_BrkCmpStsInfo:2, ChassisMgmt_FillAdressInfo:0], variable=tec_ChassisMgmtInfo}
      provided-required-interface=IF_ChassisMgmtInfo
    require port RTE_R_ComM_ACUYawRate: nonqueued-receiver-com-spec{data-element=tec_ComM_ACUYawRate, filter=data-filter-type=ALWAYS, init-value=0}, required-interface=IF_ComM_ACUYawRate
    require port RTE_R_ComM_ADCUAccMod_Enum: nonqueued-receiver-com-spec{data-element=tec_ComM_ADCUAccMod_Enum, filter=data-filter-type=ALWAYS, init-value=0}, required-interface=IF_ComM_ADCUAccMod_Enum
    require port RTE_R_ComM_ADCUPrkMod: nonqueued-receiver-com-spec{data-element=tec_ComM_ADCUPrkMod, filter=data-filter-type=ALWAYS, init-value=0}, required-interface=IF_ComM_ADCUPrkMod
    provide port RTE_P_ChassisMgmt_CrpCtrlSts: nonqueued-sender-com-spec{data-element=tec_ChassisMgmt_CrpCtrlSts, init-value=0}, provided-interface=IF_ChassisMgmt_CrpCtrlSts
    5 x require port:
      RTE_R_ComM_IBSDtcFltSts: nonqueued-receiver-com-spec{data-element=tec_ComM_IBSDtcFltSts, filter=data-filter-type=ALWAYS, init-value=0}, required-interface=IF_ComM_IBSDtcFltSts
      RTE_R_ComM_IBSPlgrPrs_mm: nonqueued-receiver-com-spec{data-element=tec_ComM_IBSPlgrPrs_mm, filter=data-filter-type=ALWAYS, init-value=0}, required-interface=IF_ComM_IBSPlgrPrs_mm
      RTE_R_ComM_EPSSteerGearAg: nonqueued-receiver-com-spec{data-element=tec_ComM_EPSSteerGearAg, filter=data-filter-type=ALWAYS, init-value=0}, required-interface=IF_ComM_EPSSteerGearAg
      RTE_R_ComM_EPSSteerGearAgVld: nonqueued-receiver-com-spec{data-element=tec_ComM_EPSSteerGearAgVld, filter=data-filter-type=ALWAYS, init-value=0}, required-interface=IF_ComM_EPSSteerGearAgVld
      RTE_R_ComM_MotActSpd_rpm: nonqueued-receiver-com-spec{data-element=tec_ComM_MotActSpd_rpm, filter=data-filter-type=ALWAYS, init-value=0}, required-interface=IF_ComM_MotActSpd_rpm
    9 x component:
      CtAp_PdlAlys: type=CtAp_PdlAlys
      CtAp_BrkMgmt: type=CtAp_BrkMgmt
      CtAp_AccrPedlDrv: type=CtAp_AccrPedlDrv
      CtAp_DrvAsscCtrl: type=CtAp_DrvAsscCtrl
      CtAp_VehStabyCtrl: type=CtAp_VehStabyCtrl
      CtAp_CrpCtrl: type=CtAp_CrpCtrl
      CtAp_CoastCtrl: type=CtAp_CoastCtrl
      CtAp_DrvTorqCoor: type=CtAp_DrvTorqCoor
      CtAp_OnePedCtrl: type=CtAp_OnePedCtrl
    delegate CtAp_PdlAlys.RTE_R_ComM_IBSAbpActv_Flg <-> outer port RTE_R_ComM_IBSAbpActv_Flg
    delegate CtAp_PdlAlys.RTE_R_ComM_IBSAebActv_Flg <-> outer port RTE_R_ComM_IBSAebActv_Flg
    delegate CtAp_PdlAlys.RTE_R_ComM_IBSBrkSts_Enum <-> outer port RTE_R_ComM_IBSBrkSts_Enum
    delegate CtAp_PdlAlys.RTE_R_ComM_IBSCdpActv_Flg <-> outer port RTE_R_ComM_IBSCdpActv_Flg
    delegate CtAp_PdlAlys.RTE_R_ComM_IBSRwuActv_Flg <-> outer port RTE_R_ComM_IBSRwuActv_Flg
    delegate CtAp_PdlAlys.RTE_R_IOAbs_AccrPedlMaiRaw_mV <-> outer port RTE_R_IOAbs_AccrPedlMaiRaw_mV
    delegate CtAp_PdlAlys.RTE_R_IOAbs_AccrPedlRdnRaw_mV <-> outer port RTE_R_IOAbs_AccrPedlRdnRaw_mV
    delegate CtAp_PdlAlys.RTE_R_ComM_IBSSts01MsgErrInfo_Bus <-> outer port RTE_R_ComM_IBSSts01MsgErrInfo_Bus
    delegate CtAp_PdlAlys.RTE_R_ComM_IBSBrkStsVld_Flg <-> outer port RTE_R_ComM_IBSBrkStsVld_Flg
    delegate CtAp_PdlAlys.RTE_R_LvMgmt_BSBattUDcNorm_Flg <-> outer port RTE_R_LvMgmt_BSBattUDcNorm_Flg
    delegate CtAp_BrkMgmt.RTE_R_ComM_NodComFailr <-> outer port RTE_R_ComM_NodComFailr
    connect CtAp_PdlAlys.RTE_P_ChassisMgmt_AccrPedlPosn_pct -> CtAp_AccrPedlDrv.RTE_R_ChassisMgmt_AccrPedlPosn_pct
    delegate CtAp_PdlAlys.RTE_P_ChassisMgmt_AccrPedlURaw1HiDTC_Bus <-> outer port RTE_P_ChassisMgmt_AccrPedlURaw1HiDTC_Bus
    delegate CtAp_PdlAlys.RTE_P_ChassisMgmt_AccrPedlURaw1LoDTC_Bus <-> outer port RTE_P_ChassisMgmt_AccrPedlURaw1LoDTC_Bus
    delegate CtAp_PdlAlys.RTE_P_ChassisMgmt_AccrPedlURaw2HiDTC_Bus <-> outer port RTE_P_ChassisMgmt_AccrPedlURaw2HiDTC_Bus
    delegate CtAp_PdlAlys.RTE_P_ChassisMgmt_AccrPedlURaw2LoDTC_Bus <-> outer port RTE_P_ChassisMgmt_AccrPedlURaw2LoDTC_Bus
    delegate CtAp_PdlAlys.RTE_P_ChassisMgmt_AccrPedlURawDifDTC_Bus <-> outer port RTE_P_ChassisMgmt_AccrPedlURawDifDTC_Bus
    delegate CtAp_PdlAlys.RTE_P_ChassisMgmt_AccrPedlVld_Flg <-> outer port RTE_P_ChassisMgmt_AccrPedlVld_Flg
    delegate CtAp_PdlAlys.RTE_P_ChassisMgmt_LimpHomeSts_Flg <-> outer port RTE_P_ChassisMgmt_LimpHome_Flg
    delegate CtAp_PdlAlys.RTE_R_ChassisMgmt_BrkSts_Enum <-> outer port RTE_R_ChassisMgmt_BrkSts_Enum
    delegate CtAp_BrkMgmt.RTE_P_ChassisMgmt_BrkCmpDecelReqActv_Flg <-> outer port RTE_P_ChassisMgmt_BrkCmpDecelReqActv_Flg
    delegate CtAp_BrkMgmt.RTE_P_ChassisMgmt_BrkCmpSts_Enum <-> outer port RTE_P_ChassisMgmt_BrkCmpSts_Enum
    delegate CtAp_BrkMgmt.RTE_P_ChassisMgmt_BrkRgnActv_Flg <-> outer port RTE_P_ChassisMgmt_BrkRgnActv_Flg
    delegate CtAp_BrkMgmt.RTE_P_ChassisMgmt_BrkRgnTq_Nm <-> outer port RTE_P_ChassisMgmt_BrkRgnTq_Nm
    delegate CtAp_BrkMgmt.RTE_P_ChassisMgmt_RgnTqCapVld_Flg <-> outer port RTE_P_ChassisMgmt_RgnTqCapVld_Flg
    delegate CtAp_BrkMgmt.RTE_P_ChassisMgmt_RgnTqCap_Nm <-> outer port RTE_P_ChassisMgmt_RgnTqCap_Nm
    delegate CtAp_BrkMgmt.RTE_P_ChassisMgmt_BrkCmpWarn_Enum <-> outer port RTE_P_ChassisMgmt_BrkCmpWarn_Enum
    delegate CtAp_AccrPedlDrv.RTE_P_ChassisMgmt_AccrPedlDesTq_Nm <-> outer port RTE_P_ChassisMgmt_AccrPedlDesTq_Nm
    delegate CtAp_DrvAsscCtrl.RTE_P_ChassisMgmt_IBSVlcReqTqAvl_Flg <-> outer port RTE_P_ChassisMgmt_IBSVlcReqTqAvl_Flg
    delegate CtAp_DrvAsscCtrl.RTE_P_ChassisMgmt_IBSVlcReqTqActv_Flg <-> outer port RTE_P_ChassisMgmt_IBSVlcReqTqActv_Flg
    delegate CtAp_DrvAsscCtrl.RTE_P_ChassisMgmt_IBSApsReqTqAvl_Flg <-> outer port RTE_P_ChassisMgmt_IBSApsReqTqAvl_Flg
    delegate CtAp_DrvAsscCtrl.RTE_P_ChassisMgmt_IBSApsReqTqActv_Flg <-> outer port RTE_P_ChassisMgmt_IBSApsReqTqActv_Flg
    delegate CtAp_VehStabyCtrl.RTE_P_ChassisMgmt_VehStbCtrlTqAvl_Flg <-> outer port RTE_P_ChassisMgmt_VehStbCtrlTqAvl_Flg
    delegate CtAp_VehStabyCtrl.RTE_P_ChassisMgmt_IBSIntvIncTqActv_Flg <-> outer port RTE_P_ChassisMgmt_IBSIntvIncTqActv_Flg
    delegate CtAp_VehStabyCtrl.RTE_P_ChassisMgmt_IBSIntvRednTqActv_Flg <-> outer port RTE_P_ChassisMgmt_IBSIntvRednTqActv_Flg
    delegate CtAp_CrpCtrl.RTE_P_ChassisMgmt_CrpCtrlDesTq_Nm <-> outer port RTE_P_ChassisMgmt_CrpCtrlDesTq_Nm
    delegate CtAp_CoastCtrl.RTE_P_ChassisMgmt_CoastCtrlDesTq_Nm <-> outer port RTE_P_ChassisMgmt_CoastCtrlDesTq_Nm
    delegate CtAp_OnePedCtrl.RTE_P_ChassisMgmt_DesVehDecelSpd_mps2q <-> outer port RTE_P_ChassisMgmt_DesVehDecelSpd_mps2q
    delegate CtAp_OnePedCtrl.RTE_P_ChassisMgmt_VehDecelSpdSts_Flg <-> outer port RTE_P_ChassisMgmt_VehDecelSpdSts_Flg
    delegate CtAp_DrvTorqCoor.RTE_P_ChassisMgmt_DrvDmdHiPrio_Flg <-> outer port RTE_P_ChassisMgmt_DrvDmdHiPrio_Flg
    delegate CtAp_PdlAlys.RTE_R_ComM_NodComFailr <-> outer port RTE_R_ComM_NodComFailr
    delegate CtAp_BrkMgmt.RTE_R_ComM_IBSDecelReqAvl_Enum <-> outer port RTE_R_ComM_IBSDecelReqAvl_Enum
    delegate CtAp_BrkMgmt.RTE_R_ComM_IBSRbsReqTqVld_Enum <-> outer port RTE_R_ComM_IBSRbsReqTqVld_Enum
    delegate CtAp_BrkMgmt.RTE_R_ComM_IBSRbsReqTq_Nm <-> outer port RTE_R_ComM_IBSRbsReqTq_Nm
    delegate CtAp_BrkMgmt.RTE_R_ComM_IBSRbsSts_Enum <-> outer port RTE_R_ComM_IBSRbsSts_Enum
    delegate CtAp_BrkMgmt.RTE_R_ComM_IVIEnaBrkCmpMod_Enum <-> outer port RTE_R_ComM_IVIEnaBrkCmpMod_Enum
    delegate CtAp_BrkMgmt.RTE_R_FctSftyMon_ActGear_Enum <-> outer port RTE_R_FctSftyMon_ActGear_Enum
    connect CtAp_AccrPedlDrv.RTE_P_ChassisMgmt_AccrPedlDesTq_Nm -> CtAp_BrkMgmt.RTE_R_ChassisMgmt_AccrPedlDesTq_Nm
    delegate CtAp_BrkMgmt.RTE_R_ComM_IBSTqMsgErrInfo_Bus <-> outer port RTE_R_ComM_IBSTqMsgErrInfo_Bus
    delegate CtAp_BrkMgmt.RTE_R_ModMgmt_ActDrvMod_Enum <-> outer port RTE_R_ModMgmt_ActDrvMod_Enum
    delegate CtAp_BrkMgmt.RTE_R_ModMgmt_HvSts_Enum <-> outer port RTE_R_ModMgmt_HvSts_Enum
    delegate CtAp_BrkMgmt.RTE_R_ErrMgmt_FobdEgyRcov_Flg <-> outer port RTE_R_ErrMgmt_FobdEgyRcov_Flg
    connect CtAp_CoastCtrl.RTE_P_ChassisMgmt_CoastCtrlDesTq_Nm -> CtAp_AccrPedlDrv.RTE_R_ChassisMgmt_CoastCtrlTq_Nm
    connect CtAp_PdlAlys.RTE_P_ChassisMgmt_AccrPedlVld_Flg -> CtAp_AccrPedlDrv.RTE_R_ChassisMgmt_AccrPedlVld_Flg
    delegate CtAp_AccrPedlDrv.RTE_R_ModMgmt_ActDrvMod_Enum <-> outer port RTE_R_ModMgmt_ActDrvMod_Enum
    delegate CtAp_AccrPedlDrv.RTE_R_FctSftyMon_ActGear_Enum <-> outer port RTE_R_FctSftyMon_ActGear_Enum
    delegate CtAp_AccrPedlDrv.RTE_R_FctSftyMon_AccrPedlTqOverFltInfo_Bus <-> outer port RTE_R_FctSftyMon_AccrPedlTqOverFltInfo_Bus
    delegate CtAp_AccrPedlDrv.RTE_R_ModMgmt_HvSts_Enum <-> outer port RTE_R_ModMgmt_HvSts_Enum
    delegate CtAp_AccrPedlDrv.RTE_R_ModMgmt_ActRgnSts_Enum <-> outer port RTE_R_ModMgmt_ActRgnSts_Enum
    delegate CtAp_AccrPedlDrv.RTE_R_VehMot_VehSpdVld_Flg <-> outer port RTE_R_VehMot_VehSpdVld_Flg
    delegate CtAp_AccrPedlDrv.RTE_R_VehMot_VehSpd_kph <-> outer port RTE_R_VehMot_VehSpd_kph
    delegate CtAp_AccrPedlDrv.RTE_R_VehMot_VehDirDif_Flg <-> outer port RTE_R_VehMot_VehDirDif_Flg
    connect CtAp_PdlAlys.RTE_R_ChassisMgmt_BrkSts_Enum -> CtAp_DrvAsscCtrl.RTE_R_ChassisMgmt_BrkSts_Enum
    delegate CtAp_DrvAsscCtrl.RTE_R_ComM_IBSACCMsgErrInfo_Bus <-> outer port RTE_R_ComM_IBSACCMsgErrInfo_Bus
    delegate CtAp_DrvAsscCtrl.RTE_R_ComM_IBSApsReqTqVld_Flg <-> outer port RTE_R_ComM_IBSApsReqTqVld_Flg
    delegate CtAp_DrvAsscCtrl.RTE_R_ComM_IBSApsReqTq_Nm <-> outer port RTE_R_ComM_IBSApsReqTq_Nm
    delegate CtAp_DrvAsscCtrl.RTE_R_ComM_IBSVlcReqTq_Nm <-> outer port RTE_R_ComM_IBSVlcReqTq_Nm
    delegate CtAp_DrvAsscCtrl.RTE_R_ComM_IBSVlcActv_Flg <-> outer port RTE_R_ComM_IBSVlcActv_Flg
    delegate CtAp_DrvAsscCtrl.RTE_R_ErrMgmt_DlyGrdtZeroTq_Flg <-> outer port RTE_R_ErrMgmt_DlyGrdtZeroTq_Flg
    delegate CtAp_DrvAsscCtrl.RTE_R_ComM_IBSVlcReqTqVld_Flg <-> outer port RTE_R_ComM_IBSVlcReqTqVld_Flg
    delegate CtAp_DrvAsscCtrl.RTE_R_ErrMgmt_ImdtZeroTq_Flg <-> outer port RTE_R_ErrMgmt_ImdtZeroTq_Flg
    delegate CtAp_DrvAsscCtrl.RTE_R_ErrMgmt_GrdtZeroTq_Flg <-> outer port RTE_R_ErrMgmt_GrdtZeroTq_Flg
    delegate CtAp_DrvAsscCtrl.RTE_R_ErrMgmt_VehSpdLimErrLv6_Flg <-> outer port RTE_R_ErrMgmt_VehSpdLimErrLv6_Flg
    delegate CtAp_DrvAsscCtrl.RTE_R_ErrMgmt_VehSpdLimErrLv5_Flg <-> outer port RTE_R_ErrMgmt_VehSpdLimErrLv5_Flg
    delegate CtAp_DrvAsscCtrl.RTE_R_LvMgmt_BSBattUDcNorm_Flg <-> outer port RTE_R_LvMgmt_BSBattUDcNorm_Flg
    delegate CtAp_DrvAsscCtrl.RTE_R_FctSftyMon_ActGear_Enum <-> outer port RTE_R_FctSftyMon_ActGear_Enum
    delegate CtAp_DrvAsscCtrl.RTE_R_VehMot_VehSpd_kph <-> outer port RTE_R_VehMot_VehSpd_kph
    delegate CtAp_DrvAsscCtrl.RTE_R_ModMgmt_HvSts_Enum <-> outer port RTE_R_ModMgmt_HvSts_Enum
    delegate CtAp_VehStabyCtrl.RTE_R_ComM_IBSDtcActv_Flg <-> outer port RTE_R_ComM_IBSDtcActv_Flg
    delegate CtAp_VehStabyCtrl.RTE_R_ComM_IBSReqIncTqSts_Flg <-> outer port RTE_R_ComM_IBSReqIncTqSts_Flg
    delegate CtAp_VehStabyCtrl.RTE_R_ComM_IBSReqIncTq_Nm <-> outer port RTE_R_ComM_IBSReqIncTq_Nm
    delegate CtAp_VehStabyCtrl.RTE_R_ComM_IBSSts02MsgErrInfo_Bus <-> outer port RTE_R_ComM_IBSSts02MsgErrInfo_Bus
    delegate CtAp_VehStabyCtrl.RTE_R_ComM_IBSReqRednTqSts_Flg <-> outer port RTE_R_ComM_IBSReqRednTqSts_Flg
    delegate CtAp_VehStabyCtrl.RTE_R_ComM_IBSReqRednTq_Nm <-> outer port RTE_R_ComM_IBSReqRednTq_Nm
    delegate CtAp_VehStabyCtrl.RTE_R_ComM_IBSVdcActv_Flg <-> outer port RTE_R_ComM_IBSVdcActv_Flg
    delegate CtAp_VehStabyCtrl.RTE_R_ComM_IBSVCUMotCtrlMsgErrInfo_Bus <-> outer port RTE_R_ComM_IBSVCUMotCtrlMsgErrInfo_Bus
    delegate CtAp_VehStabyCtrl.RTE_R_ComM_IBSTcsActv_Flg <-> outer port RTE_R_ComM_IBSTcsActv_Flg
    delegate CtAp_VehStabyCtrl.RTE_R_ErrMgmt_GrdtZeroTq_Flg <-> outer port RTE_R_ErrMgmt_GrdtZeroTq_Flg
    delegate CtAp_VehStabyCtrl.RTE_R_ErrMgmt_DlyGrdtZeroTq_Flg <-> outer port RTE_R_ErrMgmt_DlyGrdtZeroTq_Flg
    delegate CtAp_VehStabyCtrl.RTE_R_FctSftyMon_ActGear_Enum <-> outer port RTE_R_FctSftyMon_ActGear_Enum
    delegate CtAp_VehStabyCtrl.RTE_R_ErrMgmt_ImdtZeroTq_Flg <-> outer port RTE_R_ErrMgmt_ImdtZeroTq_Flg
    delegate CtAp_VehStabyCtrl.RTE_R_ModMgmt_HvSts_Enum <-> outer port RTE_R_ModMgmt_HvSts_Enum
    connect CtAp_PdlAlys.RTE_R_ChassisMgmt_BrkSts_Enum -> CtAp_CrpCtrl.RTE_R_ChassisMgmt_BrkSts_Enum
    delegate CtAp_CrpCtrl.RTE_R_ComM_IBSAvhSts_Enum <-> outer port RTE_R_ComM_IBSAvhSts_Enum
    delegate CtAp_CrpCtrl.RTE_R_ComM_IBSHdcSts_Enum <-> outer port RTE_R_ComM_IBSHdcSts_Enum
    delegate CtAp_CrpCtrl.RTE_R_ComM_IBSPlgrPrs_Bar <-> outer port RTE_R_ComM_IBSPlgrPrs_Bar
    delegate CtAp_CrpCtrl.RTE_R_VehMot_SlopGrd_pct <-> outer port RTE_R_VehMot_SlopGrd_pct
    delegate CtAp_CrpCtrl.RTE_R_ComM_IBSApsTqActv_Flg <-> outer port RTE_R_ComM_IBSApsTqActv_Flg
    delegate CtAp_CrpCtrl.RTE_R_ModMgmt_ActDrvMod_Enum <-> outer port RTE_R_ModMgmt_ActDrvMod_Enum
    delegate CtAp_CrpCtrl.RTE_R_ModMgmt_HvSts_Enum <-> outer port RTE_R_ModMgmt_HvSts_Enum
    delegate CtAp_CrpCtrl.RTE_R_VehMot_VehSpd_kph <-> outer port RTE_R_VehMot_VehSpd_kph
    delegate CtAp_CrpCtrl.RTE_R_FctSftyMon_CrpCtrlTqOverFltInfo_Bus <-> outer port RTE_R_FctSftyMon_CrpCtrlTqOverFltInfo_Bus
    delegate CtAp_CrpCtrl.RTE_R_ComM_IBSAbpActv_Flg <-> outer port RTE_R_ComM_IBSAbpActv_Flg
    delegate CtAp_CrpCtrl.RTE_R_ComM_IBSAebActv_Flg <-> outer port RTE_R_ComM_IBSAebActv_Flg
    delegate CtAp_CrpCtrl.RTE_R_ComM_IBSCdpActv_Flg <-> outer port RTE_R_ComM_IBSCdpActv_Flg
    delegate CtAp_CrpCtrl.RTE_R_ComM_IBSRwuActv_Flg <-> outer port RTE_R_ComM_IBSRwuActv_Flg
    delegate CtAp_CrpCtrl.RTE_R_FctSftyMon_ActGear_Enum <-> outer port RTE_R_FctSftyMon_ActGear_Enum
    delegate CtAp_CrpCtrl.RTE_R_VehMot_VehSpdVld_Flg <-> outer port RTE_R_VehMot_VehSpdVld_Flg
    connect CtAp_PdlAlys.RTE_P_ChassisMgmt_AccrPedlPosn_pct -> CtAp_CoastCtrl.RTE_R_ChassisMgmt_AccrPedlPosn_pct
    delegate CtAp_CoastCtrl.RTE_R_ComM_IBSHdcSts_Enum <-> outer port RTE_R_ComM_IBSHdcSts_Enum
    delegate CtAp_CoastCtrl.RTE_R_ErrMgmt_FobdEgyRcov_Flg <-> outer port RTE_R_ErrMgmt_FobdEgyRcov_Flg
    delegate CtAp_CoastCtrl.RTE_R_FctSftyMon_ActGear_Enum <-> outer port RTE_R_FctSftyMon_ActGear_Enum
    delegate CtAp_CoastCtrl.RTE_R_ModMgmt_ActRgnSts_Enum <-> outer port RTE_R_ModMgmt_ActRgnSts_Enum
    delegate CtAp_CoastCtrl.RTE_R_ModMgmt_HvSts_Enum <-> outer port RTE_R_ModMgmt_HvSts_Enum
    delegate CtAp_CoastCtrl.RTE_R_VehMot_VehSpd_kph <-> outer port RTE_R_VehMot_VehSpd_kph
    connect CtAp_PdlAlys.RTE_R_ChassisMgmt_BrkSts_Enum -> CtAp_OnePedCtrl.RTE_R_ChassisMgmt_BrkSts_Enum
    delegate CtAp_OnePedCtrl.RTE_R_ComM_IBSHdcSts_Enum <-> outer port RTE_R_ComM_IBSHdcSts_Enum
    connect CtAp_AccrPedlDrv.RTE_P_ChassisMgmt_AccrPedlDesTq_Nm -> CtAp_OnePedCtrl.RTE_R_ChassisMgmt_AccrPedlDesTq_Nm
    connect CtAp_BrkMgmt.RTE_P_ChassisMgmt_BrkCmpDecelReqActv_Flg -> CtAp_OnePedCtrl.RTE_R_ChassisMgmt_BrkCmpDecelReqActv_Flg
    delegate CtAp_OnePedCtrl.RTE_R_ModMgmt_ActDrvMod_Enum <-> outer port RTE_R_ModMgmt_ActDrvMod_Enum
    delegate CtAp_OnePedCtrl.RTE_R_ModMgmt_HvSts_Enum <-> outer port RTE_R_ModMgmt_HvSts_Enum
    delegate CtAp_OnePedCtrl.RTE_R_VehMot_VehStdl_Flg <-> outer port RTE_R_VehMot_VehStdl_Flg
    delegate CtAp_OnePedCtrl.RTE_R_FctSftyMon_DesVehDecelSpdOverFltInfo_Bus <-> outer port RTE_R_FctSftyMon_DesVehDecelSpdOverFltInfo_Bus
    delegate CtAp_OnePedCtrl.RTE_R_ComM_IBSAebActv_Flg <-> outer port RTE_R_ComM_IBSAebActv_Flg
    delegate CtAp_OnePedCtrl.RTE_R_ComM_IBSCdpActv_Flg <-> outer port RTE_R_ComM_IBSCdpActv_Flg
    delegate CtAp_OnePedCtrl.RTE_R_ComM_IBSDtcActv_Flg <-> outer port RTE_R_ComM_IBSDtcActv_Flg
    delegate CtAp_OnePedCtrl.RTE_R_ComM_IBSRwuActv_Flg <-> outer port RTE_R_ComM_IBSRwuActv_Flg
    delegate CtAp_OnePedCtrl.RTE_R_ComM_IBSTcsActv_Flg <-> outer port RTE_R_ComM_IBSTcsActv_Flg
    delegate CtAp_OnePedCtrl.RTE_R_ComM_IBSVdcActv_Flg <-> outer port RTE_R_ComM_IBSVdcActv_Flg
    delegate CtAp_OnePedCtrl.RTE_R_FctSftyMon_ActGear_Enum <-> outer port RTE_R_FctSftyMon_ActGear_Enum
    delegate CtAp_OnePedCtrl.RTE_R_VehMot_VehSpdVld_Flg <-> outer port RTE_R_VehMot_VehSpdVld_Flg
    connect CtAp_BrkMgmt.RTE_P_ChassisMgmt_BrkRgnTq_Nm -> CtAp_DrvTorqCoor.RTE_R_ChassisMgmt_BrkRgnTq_Nm
    delegate CtAp_DrvTorqCoor.RTE_R_FctSftyMon_ActGear_Enum <-> outer port RTE_R_FctSftyMon_ActGear_Enum
    connect CtAp_CrpCtrl.RTE_P_ChassisMgmt_CrpCtrlDesTq_Nm -> CtAp_DrvTorqCoor.RTE_R_ChassisMgmt_CrpCtrlDesTq_Nm
    connect CtAp_DrvAsscCtrl.RTE_P_ChassisMgmt_IBSApsReqTqActv_Flg -> CtAp_DrvTorqCoor.RTE_R_ChassisMgmt_IBSApsReqTqActv_Flg
    connect CtAp_DrvAsscCtrl.RTE_P_ChassisMgmt_IBSVlcReqTqActv_Flg -> CtAp_DrvTorqCoor.RTE_R_ChassisMgmt_IBSVlcReqTqActv_Flg
    delegate CtAp_DrvTorqCoor.RTE_R_TorqPahMgmt_MaxVehSpdLmtTq_Nm <-> outer port RTE_R_TorqPahMgmt_MaxVehSpdLmtTq_Nm
    connect CtAp_AccrPedlDrv.RTE_P_ChassisMgmt_AccrPedlDesTq_Nm -> CtAp_DrvTorqCoor.RTE_R_ChassisMgmt_AccrPedlDesTq_Nm
    connect CtAp_BrkMgmt.RTE_P_ChassisMgmt_BrkRgnActv_Flg -> CtAp_DrvTorqCoor.RTE_R_ChassisMgmt_BrkRgnActv_Flg
    delegate CtAp_PdlAlys.RTE_P_ChassisMgmt_AccrPedlPosn_pct <-> outer port RTE_P_ChassisMgmt_AccrPedlPosn_pct
    delegate CtAp_PdlAlys.RTE_P_ChassisMgmt_ErrResBrkPedlFlt_Flg <-> outer port RTE_P_ChassisMgmt_ErrResBrkPedlFlt_Flg
    delegate CtAp_CrpCtrl.RTE_R_TorqPahMgmt_EmacQstyMaxTq_Nm <-> outer port RTE_R_TorqPahMgmt_EmacQstyMaxTq_Nm
    delegate CtAp_BrkMgmt.RTE_R_TorqPahMgmt_EmacQstyMinTq_Nm <-> outer port RTE_R_TorqPahMgmt_EmacQstyMinTq_Nm
    delegate CtAp_CrpCtrl.RTE_R_TorqPahMgmt_EmacQstyMinTq_Nm <-> outer port RTE_R_TorqPahMgmt_EmacQstyMinTq_Nm
    delegate CtAp_DrvAsscCtrl.RTE_P_ChassisMgmt_IBSApsCtrlDesTqOverFltDTCInfo_Bus <-> outer port RTE_P_ChassisMgmt_IBSApsCtrlDesTqOverFltDTCInfo_Bus
    delegate CtAp_DrvAsscCtrl.RTE_P_ChassisMgmt_IBSVlcCtrlDesTqOverFltDTCInfo_Bus <-> outer port RTE_P_ChassisMgmt_IBSVlcCtrlDesTqOverFltDTCInfo_Bus
    delegate CtAp_VehStabyCtrl.RTE_P_ChassisMgmt_IBSDesIncTq_Nm <-> outer port RTE_P_ChassisMgmt_IBSDesIncTq_Nm
    delegate CtAp_VehStabyCtrl.RTE_P_ChassisMgmt_IBSDesRednTq_Nm <-> outer port RTE_P_ChassisMgmt_IBSDesRednTq_Nm
    delegate CtAp_BrkMgmt.RTE_R_LvMgmt_BSBattUDcNorm_Flg <-> outer port RTE_R_LvMgmt_BSBattUDcNorm_Flg
    delegate CtAp_DrvAsscCtrl.RTE_R_VehMot_VehSpdVld_Flg <-> outer port RTE_R_VehMot_VehSpdVld_Flg
    delegate CtAp_DrvAsscCtrl.RTE_R_ComM_IBSTqMsgErrInfo_Bus <-> outer port RTE_R_ComM_IBSTqMsgErrInfo_Bus
    delegate CtAp_DrvAsscCtrl.RTE_R_ComM_IBSApsTqActv_Flg <-> outer port RTE_R_ComM_IBSApsTqActv_Flg
    delegate CtAp_OnePedCtrl.RTE_P_ChassisMgmt_OnePedlCtrlReqStdlSts_Flg <-> outer port RTE_P_ChassisMgmt_OnePedlCtrlReqStdlSts_Flg
    delegate CtAp_OnePedCtrl.RTE_R_VehMot_Acclr2Tq_Nm <-> outer port RTE_R_VehMot_Acclr2Tq_Nm
    connect CtAp_AccrPedlDrv.RTE_P_ChassisMgmt_AccrPedlDesTq_Nm -> CtAp_CrpCtrl.RTE_R_ChassisMgmt_AccrPedlDesTq_Nm
    delegate CtAp_BrkMgmt.RTE_P_ChassisMgmt_IBSRbsDesTqOverFltDTCInfo_Bus <-> outer port RTE_P_ChassisMgmt_IBSRbsDesTqOverFltDTCInfo_Bus
    delegate CtAp_VehStabyCtrl.RTE_R_ComM_IBSSts04MsgErrInfo_Bus <-> outer port RTE_R_ComM_IBSSts04MsgErrInfo_Bus
    delegate CtAp_VehStabyCtrl.RTE_P_ChassisMgmt_IBSIntvTqActv <-> outer port RTE_P_ChassisMgmt_IBSIntvTqActv
    delegate CtAp_PdlAlys.RTE_R_IOAbs_AccrPedl1SplyVoltInfo <-> outer port RTE_R_IOAbs_AccrPedl1SplyVoltInfo
    delegate CtAp_PdlAlys.RTE_R_IOAbs_AccrPedl2SplyVoltInfo <-> outer port RTE_R_IOAbs_AccrPedl2SplyVoltInfo
    delegate CtAp_PdlAlys.RTE_R_DiagApp_DisableDCMReqInfo <-> outer port RTE_R_DiagApp_DisableDCMReqInfo
    delegate CtAp_PdlAlys.RTE_P_ChassisMgmt_AccrPedlRawPosnInfo <-> outer port RTE_P_ChassisMgmt_AccrPedlRawPosnInfo
    delegate CtAp_PdlAlys.RTE_P_ChassisMgmt_AccrPedlKdStsInfo <-> outer port RTE_P_ChassisMgmt_AccrPedlKdStsInfo
    delegate CtAp_PdlAlys.RTE_P_ChassisMgmt_AccrPedlSplyVolt1HiDTCInfo <-> outer port RTE_P_ChassisMgmt_AccrPedlSplyVolt1HiDTCInfo
    delegate CtAp_PdlAlys.RTE_P_ChassisMgmt_AccrPedlSplyVolt2LoDTCInfo <-> outer port RTE_P_ChassisMgmt_AccrPedlSplyVolt2LoDTCInfo
    delegate CtAp_PdlAlys.RTE_P_ChassisMgmt_AccrPedlSplyVolt2HiDTCInfo <-> outer port RTE_P_ChassisMgmt_AccrPedlSplyVolt2HiDTCInfo
    delegate CtAp_PdlAlys.RTE_P_ChassisMgmt_AccrPedlSplyVolt1LoDTCInfo <-> outer port RTE_P_ChassisMgmt_AccrPedlSplyVolt1LoDTCInfo
    delegate CtAp_BrkMgmt.RTE_R_ComM_IBSVlcActv_Flg <-> outer port RTE_R_ComM_IBSVlcActv_Flg
    delegate CtAp_BrkMgmt.RTE_R_DiagApp_DisableDCMReqInfo <-> outer port RTE_R_DiagApp_DisableDCMReqInfo
    delegate CtAp_DrvAsscCtrl.RTE_R_ComM_IBSCddActvInfo <-> outer port RTE_R_ComM_IBSCddActvInfo
    delegate CtAp_DrvAsscCtrl.RTE_R_DiagApp_DisableDCMReqInfo <-> outer port RTE_R_DiagApp_DisableDCMReqInfo
    delegate CtAp_DrvAsscCtrl.RTE_P_ChassisMgmt_VirtAccrPedlPosnInfo <-> outer port RTE_P_ChassisMgmt_VirtAccrPedlPosnInfo
    delegate CtAp_DrvAsscCtrl.RTE_P_ChassisMgmt_VirtAccrPedlVldInfo <-> outer port RTE_P_ChassisMgmt_VirtAccrPedlVldInfo
    delegate CtAp_CrpCtrl.RTE_R_ComM_IBSVlcActv_Flg <-> outer port RTE_R_ComM_IBSVlcActv_Flg
    delegate CtAp_CoastCtrl.RTE_R_ComM_IBSVlcActv_Flg <-> outer port RTE_R_ComM_IBSVlcActv_Flg
    delegate CtAp_OnePedCtrl.RTE_R_ComM_IBSVlcActv_Flg <-> outer port RTE_R_ComM_IBSVlcActv_Flg
    connect CtAp_PdlAlys.RTE_P_ChassisMgmt_AccrPedlRawPosnInfo -> CtAp_OnePedCtrl.RTE_R_ChassisMgmt_AccrPedlRawPosnInfo
    connect CtAp_DrvTorqCoor.RTE_P_ChassisMgmt_DrvDmdHiPrio_Flg -> CtAp_CrpCtrl.RTE_R_ChassisMgmt_DrvDmdHiPrio_Flg
    connect CtAp_AccrPedlDrv.RTE_P_ChassisMgmt_AccrPedlDesTq_Nm -> CtAp_DrvAsscCtrl.RTE_R_ChassisMgmt_AccrPedlDesTq_Nm
    delegate CtAp_DrvAsscCtrl.RTE_R_ModMgmt_ActDrvMod_Enum <-> outer port RTE_R_ModMgmt_ActDrvMod_Enum
    delegate CtAp_DrvAsscCtrl.RTE_P_ChassisMgmt_DrvAsscCtrlOvrdSts_Flg <-> outer port RTE_P_ChassisMgmt_DrvAsscCtrlOvrdSts_Flg_1
    delegate CtAp_DrvAsscCtrl.RTE_P_ChassisMgmt_IBSVlcDesTq_Nm <-> outer port RTE_P_ChassisMgmt_IBSVlcDesTq_Nm
    delegate CtAp_DrvAsscCtrl.RTE_P_ChassisMgmt_IBSApsDesTq_Nm <-> outer port RTE_P_ChassisMgmt_IBSApsDesTq_Nm
    delegate CtAp_VehStabyCtrl.RTE_R_ComM_MotActTq_Nm <-> outer port RTE_R_ComM_MotActTq_Nm
    delegate CtAp_OnePedCtrl.RTE_R_VehMot_VehDragTq_Nm <-> outer port RTE_R_VehMot_VehDragTq_Nm
    delegate CtAp_DrvTorqCoor.RTE_P_ChassisMgmt_DrvCoorrDesTq_Nm <-> outer port RTE_P_ChassisMgmt_DrvCoorrDesTq_Nm
    delegate CtAp_BrkMgmt.RTE_RP_ChassisMgmtInfo <-> outer port RTE_RP_ChassisMgmtInfo
    connect CtAp_PdlAlys.RTE_P_ChassisMgmt_AccrPedlRawPosnInfo -> CtAp_DrvAsscCtrl.RTE_R_ChassisMgmt_AccrPedlRawPosnInfo
    connect CtAp_DrvAsscCtrl.RTE_P_ChassisMgmt_IBSApsDesTq_Nm -> CtAp_DrvTorqCoor.RTE_P_ChassisMgmt_IBSApsDesTq_Nm
    connect CtAp_DrvAsscCtrl.RTE_P_ChassisMgmt_IBSVlcDesTq_Nm -> CtAp_DrvTorqCoor.RTE_P_ChassisMgmt_IBSVlcDesTq_Nm
    delegate CtAp_CoastCtrl.RTE_R_ComM_ACUYawRate <-> outer port RTE_R_ComM_ACUYawRate
    delegate CtAp_CoastCtrl.RTE_R_ModMgmt_ActDrvMod_Enum <-> outer port RTE_R_ModMgmt_ActDrvMod_Enum
    delegate CtAp_CrpCtrl.RTE_R_ComM_ADCUAccMod_Enum <-> outer port RTE_R_ComM_ADCUAccMod_Enum
    delegate CtAp_CrpCtrl.RTE_R_ComM_ADCUPrkMod <-> outer port RTE_R_ComM_ADCUPrkMod
    delegate CtAp_CrpCtrl.RTE_R_VehMot_VehDirDif_Flg <-> outer port RTE_R_VehMot_VehDirDif_Flg
    connect CtAp_AccrPedlDrv.RTE_P_ChassisMgmt_AccrPedlDesTq_Nm -> CtAp_VehStabyCtrl.RTE_R_ChassisMgmt_AccrPedlDesTq_Nm
    delegate CtAp_CrpCtrl.RTE_P_ChassisMgmt_CrpCtrlSts <-> outer port RTE_P_ChassisMgmt_CrpCtrlSts
    delegate CtAp_CoastCtrl.RTE_R_ComM_IBSDtcFltSts <-> outer port RTE_R_ComM_IBSDtcFltSts
    delegate CtAp_CrpCtrl.RTE_R_ComM_IBSPlgrPrs_mm <-> outer port RTE_R_ComM_IBSPlgrPrs_mm
    delegate CtAp_CrpCtrl.RTE_R_ComM_EPSSteerGearAg <-> outer port RTE_R_ComM_EPSSteerGearAg
    delegate CtAp_CrpCtrl.RTE_R_ComM_EPSSteerGearAgVld <-> outer port RTE_R_ComM_EPSSteerGearAgVld
    delegate CtAp_CrpCtrl.RTE_R_ComM_MotActSpd_rpm <-> outer port RTE_R_ComM_MotActSpd_rpm
